# edn: IP-XACT component
VLNV tenstorrent.com:ocah:edn:1.0

## Address spaces and blocks
edn_mmap.edn: base 'h0, range 'h48, width 32

## Registers
Registers are 32-bit, read-write, reset 0x0 unless marked. A register's access mark holds for its fields unless they carry their own. Offsets are from the block's base; lines under a group give offsets from that group; [hi:lo] are bit positions; {n}, {i} and the like mark numbered series; 'fields as' and 'values as' point back to an identical list; <NAME> marks a mode.

## edn_mmap.edn — Distributes random numbers produced by CSRNG to hardware blocks
Base 0x00000000
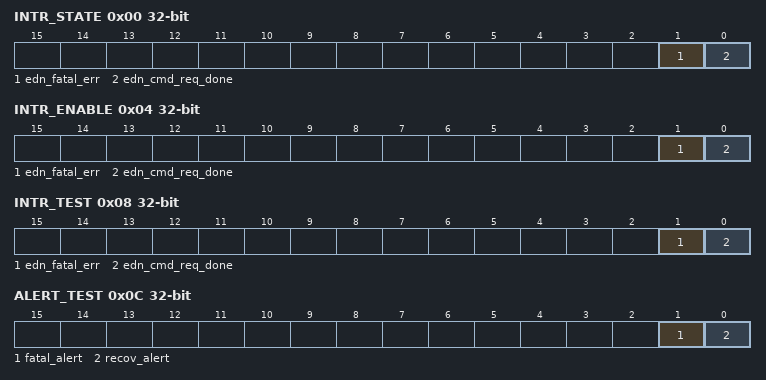
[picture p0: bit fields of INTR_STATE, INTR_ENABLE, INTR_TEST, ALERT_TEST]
0x00 INTR_STATE
  [1] edn_fatal_err write-1-clears — Asserted when a FIFO error occurs.
  [0] edn_cmd_req_done write-1-clears — Asserted when a software CSRNG request has completed.
0x04 INTR_ENABLE
  [1] edn_fatal_err — Enable interrupt when !!INTR_STATE.edn_fatal_err is set.
  [0] edn_cmd_req_done — Enable interrupt when !!INTR_STATE.edn_cmd_req_done is set.
0x08 INTR_TEST wo
  [1] edn_fatal_err — Write 1 to force !!INTR_STATE.edn_fatal_err to 1.
  [0] edn_cmd_req_done — Write 1 to force !!INTR_STATE.edn_cmd_req_done to 1.
0x0C ALERT_TEST wo
  [1] fatal_alert — Write 1 to trigger one alert event of this kind.
  [0] recov_alert — Write 1 to trigger one alert event of this kind.
0x10 REGWEN reset 0x1
  [0] REGWEN write-0-clears — When true, the CTRL can be written by software. When false, this field read-only. Defaults true, write zero to clear. Note that this needs to be cleared after initial configuration at boot in order to lock in the listed register settings.
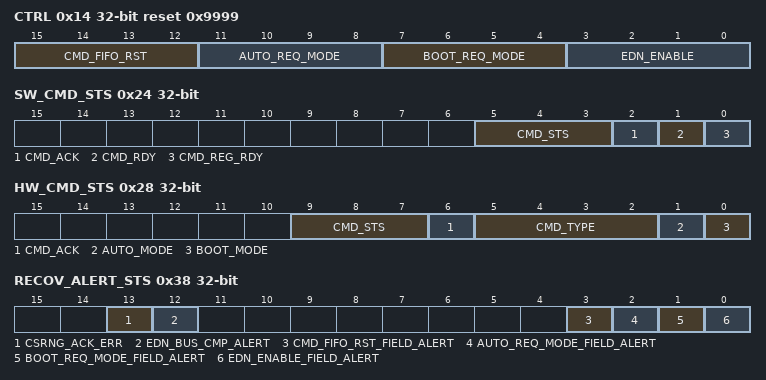
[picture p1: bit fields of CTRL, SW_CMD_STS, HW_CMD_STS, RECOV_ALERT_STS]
0x14 CTRL reset 0x9999
  [all] fields
    6=True; 9=False
  [15:12] CMD_FIFO_RST — Setting this field to kMultiBitBool4True clears the two command FIFOs: the RESEED_CMD FIFO and the GENERATE_CMD FIFO. This field must be set to the reset state by software before any further commands can be issued to these FIFOs.
  [11:8] AUTO_REQ_MODE — Setting this field to kMultiBitBool4True enables auto request mode. In this mode, EDN automatically sends `generate` and `reseed` command requests to the CSRNG application interface. The purpose of this mode is to continuously deliver entropy to endpoints without firmware intervention. For this to work, firmware has to 1) configure the !!GENERATE_CMD, !!RESEED_CMD, and !!MAX_NUM_REQS_BETWEEN_RESEEDS registers, and 2) to issue the first `instantiate` command via the !!SW_CMD_REQ register. Once this command has been acknowledged by CSRNG, the first `generate` command is sent out automatically, and a `reseed` command is sent after every MAX_NUM_REQS_BETWEEN_RESEEDS number of `generate` commands. Note that the BOOT_REQ_MODE field takes precedence over this field: If both fields are set, EDN enters boot-time request mode. If none of the fields are set, EDN enters Software Port Mode upon enabling.
  [7:4] BOOT_REQ_MODE — Setting this field to kMultiBitBool4True enables the boot-time request mode. In this mode, EDN automatically sends a boot-time request to the CSRNG application interface. The purpose of this mode is to request entropy as fast as possible after reset, and during chip boot time. Note that this takes precedence over the AUTO_REQ_MODE field: If both fields are set, EDN enters boot-time request mode. If none of the fields are set, EDN enters Software Port Mode upon enabling.
  [3:0] EDN_ENABLE — Setting this field to kMultiBitBool4True enables the EDN module. The modules of the entropy complex may only be enabled and disabled in a specific order, see Programmers Guide for details.
0x18 BOOT_INS_CMD reset 0x901
  [31:0] BOOT_INS_CMD — This field is used as the value for the `instantiate` command at boot time. See [Command Header](../../csrng/doc/theory_of_operation.md#command-header) for the meaning of the individual bits. Note that the hardware only supports a value of 0 for the `clen` field. If `clen` has a different value, EDN will hang. Fixing this requires disabling and restarting both EDN and CSRNG.
0x1C BOOT_GEN_CMD reset 0xFFF003
  [31:0] BOOT_GEN_CMD — This field is used as the value for the `generate` command at boot time. See [Command Header](../../csrng/doc/theory_of_operation.md#command-header) for the meaning of the individual bits. Note that the hardware only supports a value of 0 for the `clen` field. If `clen` has a different value, EDN will hang. Fixing this requires disabling and restarting both EDN and CSRNG.
0x20 SW_CMD_REQ wo reset not defined
  [31:0] SW_CMD_REQ — Any CSRNG action can be initiated by writing a CSRNG command to this register. Before any write operation to this register, firmware must read !!SW_CMD_STS to check whether EDN is ready to receive a new command or the next word of a previously started command. While !!CTRL.AUTO_REQ_MODE is set, only the first instantiate command has any effect. After that command has been processed, writes to this register will have no effect on operation, until !!CTRL.AUTO_REQ_MODE is de-asserted and the state machine of EDN enters the `SwPortMode` state. Refer to the [CSRNG documentation](../../csrng/doc/theory_of_operation.md#general-command-format) for details on the command format.
0x24 SW_CMD_STS ro
  [5:3] CMD_STS — This field represents the status code returned with the CSRNG application command ack. It is updated each time a SW command is acknowledged by CSRNG. To check whether a command was successful, wait for !!INTR_STATE.EDN_CMD_REQ_DONE or !!SW_CMD_STS.CMD_ACK to be high and then check the value of this field. A description of the command status types can be found [here](../../csrng/doc/registers.md#sw_cmd_sts--cmd_sts).
  [2] CMD_ACK — This one bit field indicates when a SW command has been acknowledged by the CSRNG. It is set to low each time a new command is written to !!SW_CMD_REQ. The field is set to high once a SW command request has been acknowledged by the CSRNG. 0b0: The last SW command has not been acknowledged yet. 0b1: The last SW command has been acknowledged.
  [1] CMD_RDY — This bit indicates when the EDN is ready to accept the next command. Before starting to write a new command to !!SW_CMD_REQ, this field needs to be polled. 0b0: The EDN is not ready to accept commands or the last command hasn't been acked yet. 0b1: The EDN is ready to accept the next command.
  [0] CMD_REG_RDY — This bit indicates when !!SW_CMD_REQ is ready to accept the next word. This bit has to be polled before each word of a command is written to !!SW_CMD_REQ. 0b0: The EDN is not ready to accept the next word yet. 0b1: The EDN is ready to accept the next word.
0x28 HW_CMD_STS ro
  [9:7] CMD_STS — This field represents the status code returned with the CSRNG application command ack. It is updated each time a HW command is acknowledged by CSRNG. A description of the command status types can be found [here](../../csrng/doc/registers.md#sw_cmd_sts--cmd_sts).
  [6] CMD_ACK — This one bit field indicates when a HW command has been acknowledged by the CSRNG. It is set to low each time a new command is sent to the CSRNG. The field is set to high once a HW command request has been acknowledged by the CSRNG. 0b0: The last HW command has not been acknowledged yet. 0b1: The last HW command has been acknowledged.
  [5:2] CMD_TYPE — This field contains the application command type of the hardware controlled command issued last. The application command selects one of five operations to perform. A description of the application command types can be found [here](../../csrng/doc/theory_of_operation.md#command-description).
  [1] AUTO_MODE — This one bit field indicates whether the EDN is in the hardware controlled part of auto mode. The instantiate command is issued via SW interface and is thus not part of the hardware controlled part of auto mode. 0b0: The EDN is not in the hardware controlled part of auto mode. 0b1: The EDN is in the hardware controlled part of auto mode.
  [0] BOOT_MODE — This one bit field indicates whether the EDN is in the hardware controlled boot mode. 0b0: The EDN is not in boot mode. 0b1: The EDN is in boot mode.
0x2C RESEED_CMD wo reset not defined
  [31:0] RESEED_CMD — Writing this register will fill a FIFO with up to 13 command words (32b words). When running in auto request mode, this FIFO is used to automatically send out a `reseed` command to the CSRNG application interface after every MAX_NUM_REQS_BETWEEN_RESEEDS number of `generate` commands. See [General Command Format](../../csrng/doc/theory_of_operation.md#general-command-format) for details about the command format. Note that the number of additional data words provided must match the value of the `clen` field of the first word. Otherwise, undefined behavior may result. If more than 13 entries are written to the FIFO, they are ignored and EDN signals an `edn_fatal_err` interrupt as well as a fatal alert.
0x30 GENERATE_CMD wo reset not defined
  [31:0] GENERATE_CMD — Writing this register will fill a FIFO with up to 13 command words (32b words). When running auto request mode, this FIFO is used to automatically send out `generate` commands to the CSRNG application interface. See [General Command Format](../../csrng/doc/theory_of_operation.md#general-command-format) for details about the command format. Note that the number of additional data words provided must match the value of the `clen` field of the first word. Otherwise, undefined behavior may result. If more than 13 entries are written to the FIFO, they are ignored and EDN signals an `edn_fatal_err` interrupt as well as a fatal alert.
0x34 MAX_NUM_REQS_BETWEEN_RESEEDS
  [31:0] MAX_NUM_REQS_BETWEEN_RESEEDS — Setting this field will set the number of `generate` command requests that are made to CSRNG before a reseed request is made. This value only has meaning when running in auto request mode. This register supports a maximum of 2^32 `generate` requests between reseeds. This register will be used by a counter that counts down, triggering an automatic `reseed` request when it reaches zero. Note that this value must be chosen smaller than or equal to the value configured in the [`RESEED_INTERVAL` register of CSRNG](../../csrng/doc/registers.md#reseed-interval).
0x38 RECOV_ALERT_STS
  [13] CSRNG_ACK_ERR write-0-clears — This bit is set when the CSRNG returns an acknowledgement where the status signal is non-zero. Writing a zero resets this status bit.
  [12] EDN_BUS_CMP_ALERT write-0-clears — This bit is set when the interal entropy bus value is equal to the prior valid value on the bus, indicating a possible attack. Writing a zero resets this status bit.
  [3] CMD_FIFO_RST_FIELD_ALERT write-0-clears — This bit is set when the CMD_FIFO_RST field is set to an illegal value, something other than kMultiBitBool4True or kMultiBitBool4False. Writing a zero resets this status bit.
  [2] AUTO_REQ_MODE_FIELD_ALERT write-0-clears — This bit is set when the !!CTRL.AUTO_REQ_MODE field is set to an illegal value, something other than kMultiBitBool4True or kMultiBitBool4False. Writing a zero resets this status bit.
  [1] BOOT_REQ_MODE_FIELD_ALERT write-0-clears — This bit is set when the BOOT_REQ_MODE field is set to an illegal value, something other than kMultiBitBool4True or kMultiBitBool4False. Writing a zero resets this status bit.
  [0] EDN_ENABLE_FIELD_ALERT write-0-clears — This bit is set when the EDN_ENABLE field is set to an illegal value, something other than kMultiBitBool4True or kMultiBitBool4False. Writing a zero resets this status bit.
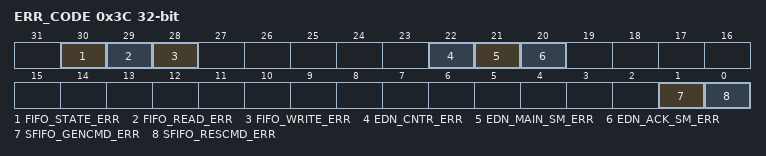
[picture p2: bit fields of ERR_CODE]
0x3C ERR_CODE ro
  [30] FIFO_STATE_ERR — This bit will be set to one when any of the source bits (bits 0 through 1 of this register) are asserted as a result of an error pulse generated from any FIFO where both the empty and full status bits are set or in case of error conditions inside the hardened counters. This bit will stay set until the next reset.
  [29] FIFO_READ_ERR — This bit will be set to one when any of the source bits (bits 0 through 1 of this register) are asserted as a result of an error pulse generated from any empty FIFO that has received a read pulse. This bit will stay set until the next reset.
  [28] FIFO_WRITE_ERR — This bit will be set to one when any of the source bits (bits 0 through 1 of this register) are asserted as a result of an error pulse generated from any full FIFO that has received a write pulse. This bit will stay set until the next reset.
  [22] EDN_CNTR_ERR — This bit will be set to one when a hardened counter has detected an error condition. This error will signal a fatal alert. This bit will stay set until the next reset.
  [21] EDN_MAIN_SM_ERR — This bit will be set to one when an illegal state has been detected for the EDN main stage state machine. This error will signal a fatal alert. This bit will stay set until the next reset.
  [20] EDN_ACK_SM_ERR — This bit will be set to one when an illegal state has been detected for the EDN ack stage state machine. This error will signal a fatal alert. This bit will stay set until the next reset.
  [1] SFIFO_GENCMD_ERR — This bit will be set to one when an error has been detected for the generate command FIFO. The type of error is reflected in the type status bits (bits 28 through 30 of this register). When this bit is set, a fatal error condition will result. This bit will stay set until the next reset.
  [0] SFIFO_RESCMD_ERR — This bit will be set to one when an error has been detected for the reseed command FIFO. The type of error is reflected in the type status bits (bits 28 through 30 of this register). When this bit is set, a fatal error condition will result.
0x40 ERR_CODE_TEST
  [4:0] ERR_CODE_TEST — Setting this field will set the bit number for which an error will be forced in the hardware. This bit number is that same one found in the !!ERR_CODE register. The action of writing this register will force an error pulse. The sole purpose of this register is to test that any error properly propagates to either an interrupt or an alert.
0x44 MAIN_SM_STATE ro reset 0xC1
  [8:0] MAIN_SM_STATE — This is the state of the EDN main state machine. See the RTL file `edn_main_sm` for the meaning of the values.

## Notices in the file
SPDX-License-Identifier: Apache-2.0
SPDX-FileCopyrightText: 2026 Tenstorrent USA, Inc.
